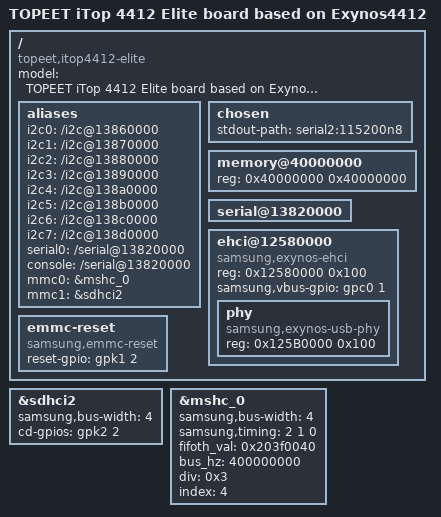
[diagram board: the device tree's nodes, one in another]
/*
 * TOPEET's Exynos4412 based itop board device tree source
 *
 * Copyright (c) 2018 Samsung Electronics Co., Ltd.
 *		http://www.samsung.com
 *
 * SPDX-License-Identifier:	GPL-2.0+
 */

/dts-v1/;
#include "exynos4412.dtsi"

/ {
	model = "TOPEET iTop 4412 Elite board based on Exynos4412";
	compatible = "topeet,itop4412-elite", "samsung,exynos4412";

	aliases {
		i2c0 = "/i2c@13860000";
		i2c1 = "/i2c@13870000";
		i2c2 = "/i2c@13880000";
		i2c3 = "/i2c@13890000";
		i2c4 = "/i2c@138a0000";
		i2c5 = "/i2c@138b0000";
		i2c6 = "/i2c@138c0000";
		i2c7 = "/i2c@138d0000";
		serial0 = "/serial@13820000";
		console = "/serial@13820000";
		mmc0 = &mshc_0;
		mmc1 = &sdhci2;
	};

	chosen {
		stdout-path = "serial2:115200n8";
	};

	memory@40000000 {
		device_type = "memory";
		reg = <0x40000000 0x40000000>;
	};

	serial@13820000 {
		status = "okay";
	};

	ehci@12580000 {
		compatible = "samsung,exynos-ehci";
		reg = <0x12580000 0x100>;
		#address-cells = <1>;
		#size-cells = <1>;
		status = "okay";
		/* In order to reset USB ethernet */
		samsung,vbus-gpio = <&gpc0 1 0>;
		phy {
			compatible = "samsung,exynos-usb-phy";
			reg = <0x125B0000 0x100>;
		};
	};

	emmc-reset {
		compatible = "samsung,emmc-reset";
		reset-gpio = <&gpk1 2 0>;
	};

/*
	usb-phy-reset {
		compatible = "smsc,usb-phy-reset";
		reset-gpio = <&gpm2 4 GPIO_ACTIVE_LOW>;
	};*/
};

&sdhci2 {
	samsung,bus-width = <4>;
	/* cd-gpios = <&gpx0 7 0>; */
	cd-gpios = <&gpk2 2 0>;
	status = "okay";
};

&mshc_0 {
	samsung,bus-width = <4>;
	samsung,timing = <2 1 0>;
	fifoth_val = <0x203f0040>;
	bus_hz = <400000000>;
	div = <0x3>;
	index = <4>;
	status = "okay";
};
